# ADuCM4050 register map
Vendor: Analog Devices; Series: ADuCM4050; File version: 1p0
CPU: CM4 r0p1, little endian, MPU, FPU, 3 interrupt priority bits
Registers are 32-bit, read-write, reset 0x0 unless marked. A register's access mark holds for its fields unless they carry their own. Offsets are from the block's base; [hi:lo] are bit positions.

## CLKG0_CLK — Clocking
Base 0x4004C300
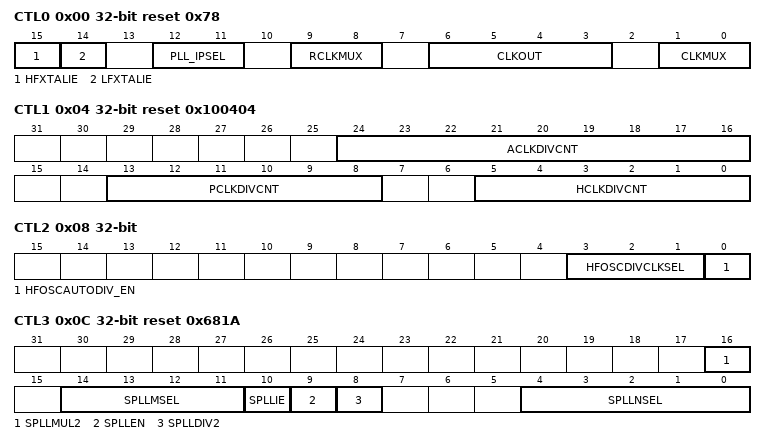
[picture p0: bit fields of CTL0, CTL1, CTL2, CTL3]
0x00 CTL0 reset 0x78 — Misc Clock Settings
  [15] HFXTALIE — High frequency crystal interrupt enable
  [14] LFXTALIE — Low frequency crystal interrupt enable
  [12:11] PLL_IPSEL — SPLL source select mux
    0=PLL_HFOSC (Internal HF oscillator is selected); 1=PLL_HFXTAL (External HF XTAL oscillator is selected); 2=PLL_GPIO (GPIO_CLK input is selected); 3=PLL_GPIO1 (GPIO_CLK input is selected)
  [9:8] RCLKMUX — Flash reference clock and HPBUCK clock source mux
  [6:3] CLKOUT — GPIO clock out select
  [1:0] CLKMUX — Clock mux select
0x04 CTL1 reset 0x100404 — Clock Dividers
  [24:16] ACLKDIVCNT range 0x00000000..0x000001FF — ACLK Divide Count
  [13:8] PCLKDIVCNT range 0x00000000..0x0000003F — PCLK divide count
  [5:0] HCLKDIVCNT range 0x00000000..0x0000003F — HCLK divide count
0x08 CTL2 — HF Oscillator Divided Clock Select
  [3:1] HFOSCDIVCLKSEL — HF Oscillator divided clock select
  [0] HFOSCAUTODIV_EN — HF Oscillator auto divide by one clock selection during wakeup from Flexi power mode
0x0C CTL3 reset 0x681A — System PLL
  [16] SPLLMUL2 — System PLL multiply by 2
  [14:11] SPLLMSEL range 0x00000000..0x0000000F — System PLL M Divider
  [10] SPLLIE — System PLL interrupt enable
  [9] SPLLEN — System PLL enable
  [8] SPLLDIV2 — System PLL division by 2
  [4:0] SPLLNSEL range 0x00000000..0x0000001F — System PLL N multiplier
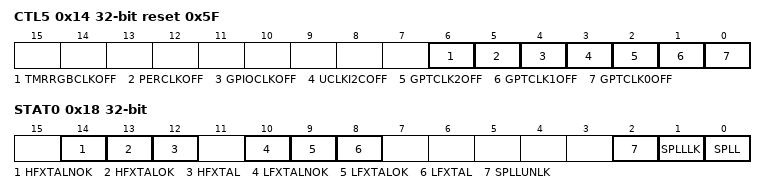
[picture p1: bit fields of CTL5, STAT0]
0x14 CTL5 reset 0x5F — User Clock Gating Control
  [6] TMRRGBCLKOFF — Timer RGB user control
  [5] PERCLKOFF — This bit is used to disable all clocks connected to all peripherals
  [4] GPIOCLKOFF — GPIO clock control
  [3] UCLKI2COFF — I2C clock user control
  [2] GPTCLK2OFF — GP Timer 2 user control
  [1] GPTCLK1OFF — GP Timer 1 user control
  [0] GPTCLK0OFF — GP Timer 0 user control
0x18 STAT0 — Clocking Status
  [14] HFXTALNOK — HF crystal not stable
  [13] HFXTALOK — HF crystal stable
  [12] HFXTAL ro — HF crystal status
  [10] LFXTALNOK — LF crystal not stable
  [9] LFXTALOK — LF crystal stable
  [8] LFXTAL ro — LF crystal status
  [2] SPLLUNLK — System PLL unlock
  [1] SPLLLK — System PLL lock
  [0] SPLL ro — System PLL status

## BUSM0 — Bus matrix
Base 0x4004C800
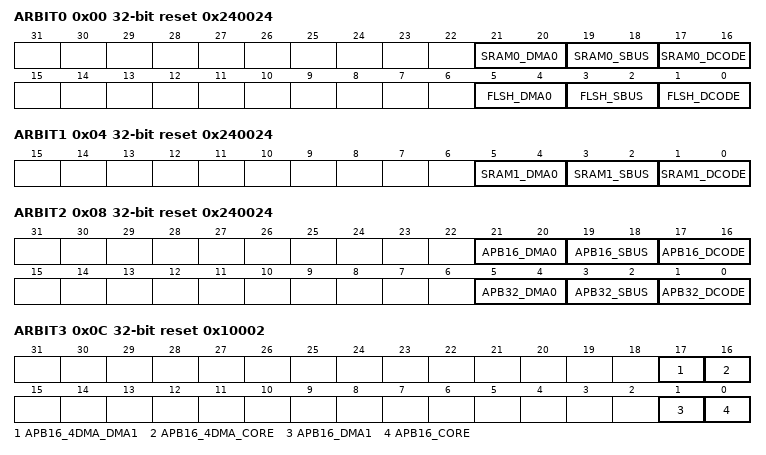
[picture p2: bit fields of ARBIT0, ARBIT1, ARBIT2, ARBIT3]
0x00 ARBIT0 reset 0x240024 — Arbitration Priority Configuration for FLASH and SRAM0
  [21:20] SRAM0_DMA0 range 0x00000000..0x00000003 — SRAM0 priority for DMA0
  [19:18] SRAM0_SBUS range 0x00000000..0x00000003 — SRAM0 priority for SBUS
  [17:16] SRAM0_DCODE range 0x00000000..0x00000003 — SRAM0 priority for Dcode
  [5:4] FLSH_DMA0 range 0x00000000..0x00000003 — Flash priority for DMA0
  [3:2] FLSH_SBUS range 0x00000000..0x00000003 — Flash priority for SBUS
  [1:0] FLSH_DCODE range 0x00000000..0x00000003 — Flash priority for DCODE
0x04 ARBIT1 reset 0x240024 — Arbitration Priority Configuration for SRAM1
  [5:4] SRAM1_DMA0 range 0x00000000..0x00000003 — SRAM1 priority for DMA0
  [3:2] SRAM1_SBUS range 0x00000000..0x00000003 — SRAM1 priority for SBUS
  [1:0] SRAM1_DCODE range 0x00000000..0x00000003 — SRAM1 priority for Dcode
0x08 ARBIT2 reset 0x240024 — Arbitration Priority Configuration for APB32 and APB16
  [21:20] APB16_DMA0 range 0x00000000..0x00000003 — APB16 priority for DMA0
  [19:18] APB16_SBUS range 0x00000000..0x00000003 — APB16 priority for SBUS
  [17:16] APB16_DCODE range 0x00000000..0x00000003 — APB16 priority for DCODE
  [5:4] APB32_DMA0 range 0x00000000..0x00000003 — APB32 priority for DMA0
  [3:2] APB32_SBUS range 0x00000000..0x00000003 — APB32 priority for SBUS
  [1:0] APB32_DCODE range 0x00000000..0x00000003 — APB32 priority for DCODE
0x0C ARBIT3 reset 0x10002 — Arbitration Priority Configuration for APB16 priority for core and for DMA1
  [17] APB16_4DMA_DMA1 range 0x00000000..0x00000001 — APB16 for dma priority for DMA1
  [16] APB16_4DMA_CORE range 0x00000000..0x00000001 — APB16 for dma priority for CORE
  [1] APB16_DMA1 range 0x00000000..0x00000001 — APB16 priority for DMA1
  [0] APB16_CORE range 0x00000000..0x00000001 — APB16 priority for CORE
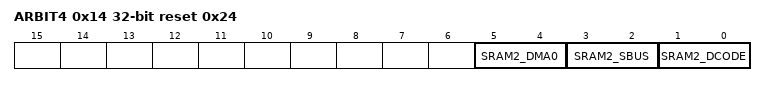
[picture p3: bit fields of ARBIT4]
0x14 ARBIT4 reset 0x24 — Arbitration Priority Configuration for SRAM1 and SIP
  [5:4] SRAM2_DMA0 range 0x00000000..0x00000003 — SRAM2 priority for DMA0
  [3:2] SRAM2_SBUS range 0x00000000..0x00000003 — SRAM2 priority for SBUS
  [1:0] SRAM2_DCODE range 0x00000000..0x00000003 — SRAM2 priority for Dcode
